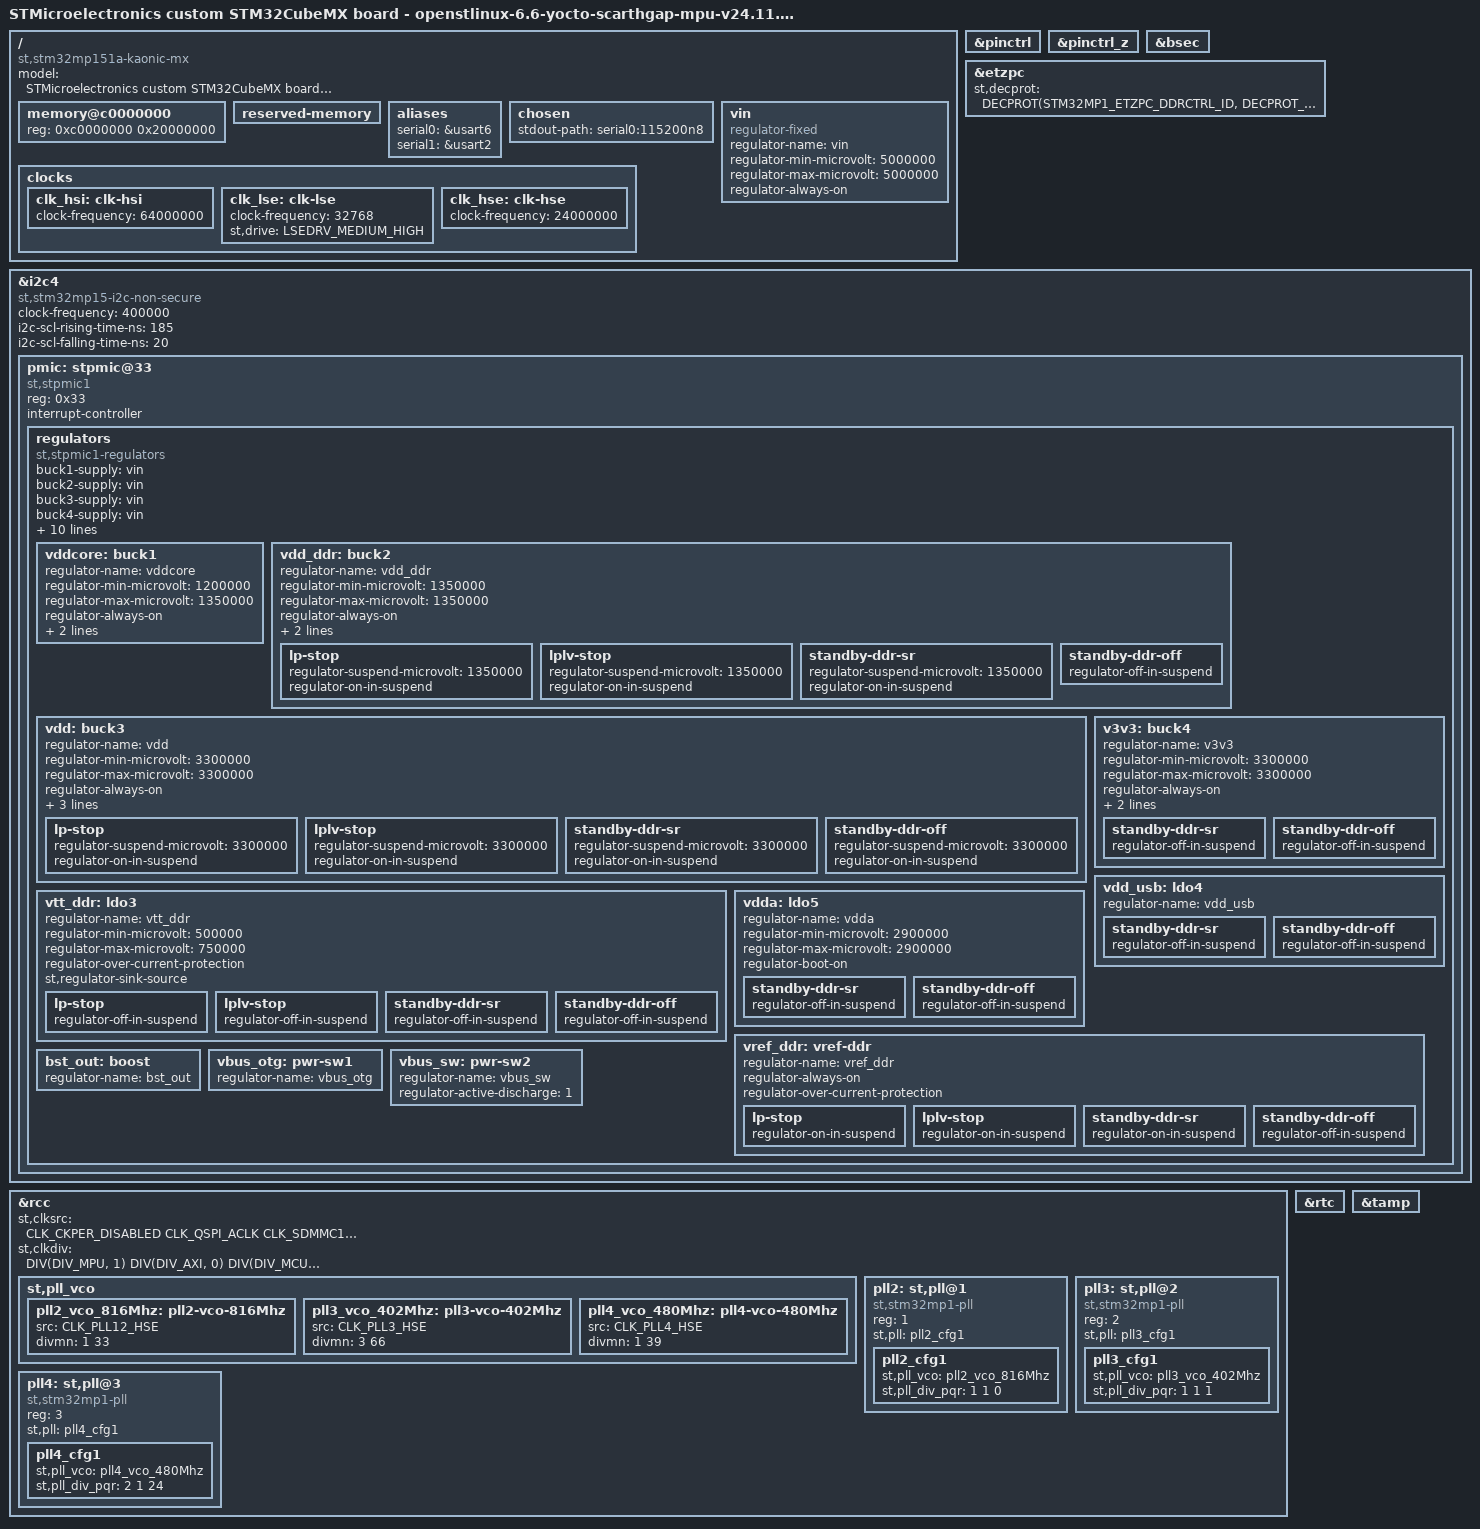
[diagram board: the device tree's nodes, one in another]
// SPDX-License-Identifier: (GPL-2.0-or-later OR BSD-3-Clause)
/*
 * Copyright (C) 2025, STMicroelectronics - All Rights Reserved
 * Author: STM32CubeMX code generation for STMicroelectronics.
 */

/* For more information on Device Tree configuration, please refer to
 * https://wiki.st.com/stm32mpu/wiki/Category:Device_tree_configuration
 */

/dts-v1/;

#include <dt-bindings/pinctrl/stm32-pinfunc.h>
#include <dt-bindings/clock/stm32mp1-clksrc.h>
#include <dt-bindings/soc/stm32mp15-etzpc.h>
#include "stm32mp151.dtsi"
#include "stm32mp15xa.dtsi"
#include "stm32mp15xxab-pinctrl.dtsi"

/* USER CODE BEGIN includes */
#include <dt-bindings/mfd/st,stpmic1.h>
/* USER CODE END includes */

/ {
	model = "STMicroelectronics custom STM32CubeMX board - openstlinux-6.6-yocto-scarthgap-mpu-v24.11.06";
	compatible = "st,stm32mp151a-kaonic-mx", "st,stm32mp151";

	memory@c0000000 {
		device_type = "memory";
		reg = <0xc0000000 0x20000000>;

		/* USER CODE BEGIN memory */
		/* USER CODE END memory */
	};

	reserved-memory {
		#address-cells = <1>;
		#size-cells = <1>;
		ranges;

		/* USER CODE BEGIN reserved-memory */
		/* USER CODE END reserved-memory */
	};

	/* USER CODE BEGIN root */

	aliases {
		serial0 = &usart6;
		serial1 = &usart2;
	};

	chosen {
		stdout-path = "serial0:115200n8";
	};


	vin: vin {
		compatible = "regulator-fixed";
		regulator-name = "vin";
		regulator-min-microvolt = <5000000>;
		regulator-max-microvolt = <5000000>;
		regulator-always-on;
	};

	/* USER CODE END root */

	clocks {
		/* USER CODE BEGIN clocks */
		/* USER CODE END clocks */

		clk_hsi: clk-hsi {
			clock-frequency = <64000000>;

			/* USER CODE BEGIN clk_hsi */
			/* USER CODE END clk_hsi */
		};
		clk_lse: clk-lse {
			clock-frequency = <32768>;
			st,drive = < LSEDRV_MEDIUM_HIGH >;

			/* USER CODE BEGIN clk_lse */
			/* USER CODE END clk_lse */
		};
		clk_hse: clk-hse {
			clock-frequency = <24000000>;

			/* USER CODE BEGIN clk_hse */
			/* USER CODE END clk_hse */
		};
	};

}; /*root*/

/*Warning: the configuration of the secured GPIOs should be added in (addons) User Section*/
&pinctrl {
	/* USER CODE BEGIN pinctrl */
	/* USER CODE END pinctrl */
};

&pinctrl_z {
	/* USER CODE BEGIN pinctrl_z */
	/* USER CODE END pinctrl_z */
};

&bsec {
	status = "okay";

	/* USER CODE BEGIN bsec */
	/* USER CODE END bsec */
};

&etzpc {
	status = "okay";
	st,decprot = <
	/*"NS_R S_W" peripherals*/
	DECPROT(STM32MP1_ETZPC_DDRCTRL_ID, DECPROT_NS_R_S_W, DECPROT_LOCK)
	DECPROT(STM32MP1_ETZPC_DDRPHYC_ID, DECPROT_NS_R_S_W, DECPROT_LOCK)
	/*"Non Secured" peripherals*/
	DECPROT(STM32MP1_ETZPC_DMA1_ID, DECPROT_NS_RW, DECPROT_UNLOCK)
	DECPROT(STM32MP1_ETZPC_DMAMUX_ID, DECPROT_NS_RW, DECPROT_UNLOCK)
	DECPROT(STM32MP1_ETZPC_I2C2_ID, DECPROT_NS_RW, DECPROT_UNLOCK)
	DECPROT(STM32MP1_ETZPC_I2C4_ID, DECPROT_NS_RW, DECPROT_UNLOCK)
	DECPROT(STM32MP1_ETZPC_QSPI_ID, DECPROT_NS_RW, DECPROT_UNLOCK)
	DECPROT(STM32MP1_ETZPC_DLYBQ_ID, DECPROT_NS_RW, DECPROT_UNLOCK)
	DECPROT(STM32MP1_ETZPC_SPI3_ID, DECPROT_NS_RW, DECPROT_UNLOCK)
	DECPROT(STM32MP1_ETZPC_SPI4_ID, DECPROT_NS_RW, DECPROT_UNLOCK)
	DECPROT(STM32MP1_ETZPC_SPI6_ID, DECPROT_NS_RW, DECPROT_UNLOCK)
	DECPROT(STM32MP1_ETZPC_USART2_ID, DECPROT_NS_RW, DECPROT_UNLOCK)
	DECPROT(STM32MP1_ETZPC_USART6_ID, DECPROT_NS_RW, DECPROT_UNLOCK)
	DECPROT(STM32MP1_ETZPC_OTG_ID, DECPROT_NS_RW, DECPROT_UNLOCK)
	/*"Secured" peripherals*/
	DECPROT(STM32MP1_ETZPC_STGENC_ID, DECPROT_S_RW, DECPROT_UNLOCK)
	/*"Mcu Isolation" peripherals*/
	DECPROT(STM32MP1_ETZPC_DMA2_ID, DECPROT_MCU_ISOLATION, DECPROT_UNLOCK)

	/*Restriction: following IDs are not managed  - please to use User-Section if needed:
		  STM32MP1_ETZPC_SRAMx_ID  STM32MP1_ETZPC_RETRAM_ID  STM32MP1_ETZPC_BKPSRAM_ID*/

	/* USER CODE BEGIN etzpc_decprot */
		/*STM32CubeMX generates a basic and standard configuration for ETZPC.
		Additional device configurations can be added here if needed.
		"etzpc" node could be also overloaded in "addons" User-Section.*/
	/* USER CODE END etzpc_decprot */
	>;

	/* USER CODE BEGIN etzpc */
	/* USER CODE END etzpc */
};

&i2c4 {
	status = "okay";

	/* USER CODE BEGIN i2c4 */
	compatible = "st,stm32mp15-i2c-non-secure";

	clock-frequency = <400000>;
	i2c-scl-rising-time-ns = <185>;
	i2c-scl-falling-time-ns = <20>;

	pmic: stpmic@33 {
		compatible = "st,stpmic1";
		reg = <0x33>;
		interrupt-controller;
		#interrupt-cells = <2>;
		status = "okay";

		regulators {
			compatible = "st,stpmic1-regulators";

			buck1-supply = <&vin>;
			buck2-supply = <&vin>;
			buck3-supply = <&vin>;
			buck4-supply = <&vin>;

			ldo1-supply = <&v3v3>;
			ldo2-supply = <&vin>;
			ldo3-supply = <&vdd_ddr>;
			ldo4-supply = <&vin>;
			ldo5-supply = <&vin>;
			ldo6-supply = <&v3v3>;

			vref_ddr-supply = <&vin>;
			boost-supply = <&vin>;

			pwr_sw1-supply = <&bst_out>;
			pwr_sw2-supply = <&bst_out>;

			vddcore: buck1 {
				regulator-name = "vddcore";
				regulator-min-microvolt = <1200000>;
				regulator-max-microvolt = <1350000>;
				regulator-always-on;
				regulator-initial-mode = <0>;
				regulator-over-current-protection;
			};

			vdd_ddr: buck2 {
				regulator-name = "vdd_ddr";
				regulator-min-microvolt = <1350000>;
				regulator-max-microvolt = <1350000>;
				regulator-always-on;
				regulator-initial-mode = <0>;
				regulator-over-current-protection;

				lp-stop {
					regulator-suspend-microvolt = <1350000>;
					regulator-on-in-suspend;
				};

				lplv-stop {
					regulator-suspend-microvolt = <1350000>;
					regulator-on-in-suspend;
				};

				standby-ddr-sr {
					regulator-suspend-microvolt = <1350000>;
					regulator-on-in-suspend;
				};

				standby-ddr-off {
					regulator-off-in-suspend;
				};
			};

			vdd: buck3 {
				regulator-name = "vdd";
				regulator-min-microvolt = <3300000>;
				regulator-max-microvolt = <3300000>;
				regulator-always-on;
				st,mask-reset;
				regulator-initial-mode = <0>;
				regulator-over-current-protection;

				lp-stop {
					regulator-suspend-microvolt = <3300000>;
					regulator-on-in-suspend;
				};

				lplv-stop {
					regulator-suspend-microvolt = <3300000>;
					regulator-on-in-suspend;
				};

				standby-ddr-sr {
					regulator-suspend-microvolt = <3300000>;
					regulator-on-in-suspend;
				};

				standby-ddr-off {
					regulator-suspend-microvolt = <3300000>;
					regulator-on-in-suspend;
				};
			};

			v3v3: buck4 {
				regulator-name = "v3v3";
				regulator-min-microvolt = <3300000>;
				regulator-max-microvolt = <3300000>;
				regulator-always-on;
				regulator-over-current-protection;
				regulator-initial-mode = <0>;

				standby-ddr-sr {
					regulator-off-in-suspend;
				};

				standby-ddr-off {
					regulator-off-in-suspend;
				};
			};

			vtt_ddr: ldo3 {
				regulator-name = "vtt_ddr";
				regulator-min-microvolt = <500000>;
				regulator-max-microvolt = <750000>;
				regulator-over-current-protection;
				st,regulator-sink-source;

				lp-stop {
					regulator-off-in-suspend;
				};

				lplv-stop {
					regulator-off-in-suspend;
				};

				standby-ddr-sr {
					regulator-off-in-suspend;
				};

				standby-ddr-off {
					regulator-off-in-suspend;
				};
			};

			vdd_usb: ldo4 {
				regulator-name = "vdd_usb";

				standby-ddr-sr {
					regulator-off-in-suspend;
				};

				standby-ddr-off {
					regulator-off-in-suspend;
				};
			};

			vdda: ldo5 {
				regulator-name = "vdda";
				regulator-min-microvolt = <2900000>;
				regulator-max-microvolt = <2900000>;
				regulator-boot-on;

				standby-ddr-sr {
					regulator-off-in-suspend;
				};

				standby-ddr-off {
					regulator-off-in-suspend;
				};
			};

			vref_ddr: vref-ddr {
				regulator-name = "vref_ddr";
				regulator-always-on;
				regulator-over-current-protection;

				lp-stop {
					regulator-on-in-suspend;
				};

				lplv-stop {
					regulator-on-in-suspend;
				};

				standby-ddr-sr {
					regulator-on-in-suspend;
				};

				standby-ddr-off {
					regulator-off-in-suspend;
				};
			};

			bst_out: boost {
				regulator-name = "bst_out";
			};

			vbus_otg: pwr-sw1 {
				regulator-name = "vbus_otg";
			};

			vbus_sw: pwr-sw2 {
				regulator-name = "vbus_sw";
				regulator-active-discharge = <1>;
			};
		};
	};

	/* USER CODE END i2c4 */
};

&rcc {
	status = "okay";

	/* USER CODE BEGIN rcc */
	/* USER CODE END rcc */

	st,clksrc = <
		CLK_CKPER_DISABLED
		CLK_QSPI_ACLK
		CLK_SDMMC12_HCLK6
		CLK_STGEN_HSI
		CLK_SPI2S23_PLL4P
		CLK_SPI45_PCLK2
		CLK_SPI6_PCLK5
		CLK_I2C46_PCLK5
		CLK_USBO_PLL4R
		CLK_I2C12_PCLK1
		CLK_UART24_PCLK1
		CLK_UART6_PCLK2
		CLK_MPU_HSI
		CLK_AXI_HSE
		CLK_MCU_PLL3P
		CLK_RTC_LSE
		CLK_MCO1_DISABLED
		CLK_MCO2_DISABLED
	>;
	st,clkdiv = <
		DIV(DIV_MPU, 1)
		DIV(DIV_AXI, 0)
		DIV(DIV_MCU, 0)
		DIV(DIV_APB1, 1)
		DIV(DIV_APB2, 1)
		DIV(DIV_APB3, 1)
		DIV(DIV_APB4, 0)
		DIV(DIV_APB5, 0)
		DIV(DIV_RTC, 0)
		DIV(DIV_MCO1, 0)
		DIV(DIV_MCO2, 0)
	>;
	st,pll_vco {
		pll2_vco_816Mhz: pll2-vco-816Mhz {
			src = < CLK_PLL12_HSE >;
			divmn = < 1 33 >;
		};
		pll3_vco_402Mhz: pll3-vco-402Mhz {
			src = < CLK_PLL3_HSE >;
			divmn = < 3 66 >;
		};
		pll4_vco_480Mhz: pll4-vco-480Mhz {
			src = < CLK_PLL4_HSE >;
			divmn = < 1 39 >;
		};
		/* USER CODE BEGIN rcc_st-pll_vco */
		/* USER CODE END rcc_st-pll_vco */
	};

	pll2:st,pll@1 {
		compatible = "st,stm32mp1-pll";
		reg = <1>;

		st,pll = < &pll2_cfg1 >;

		pll2_cfg1: pll2_cfg1 {
			st,pll_vco = < &pll2_vco_816Mhz >;
			st,pll_div_pqr = < 1 1 0 >;
		};
		/* USER CODE BEGIN pll2 */
		/* USER CODE END pll2 */
	};

	pll3:st,pll@2 {
		compatible = "st,stm32mp1-pll";
		reg = <2>;

		st,pll = < &pll3_cfg1 >;

		pll3_cfg1: pll3_cfg1 {
			st,pll_vco = < &pll3_vco_402Mhz >;
			st,pll_div_pqr = < 1 1 1 >;
		};
		/* USER CODE BEGIN pll3 */
		/* USER CODE END pll3 */
	};

	pll4:st,pll@3 {
		compatible = "st,stm32mp1-pll";
		reg = <3>;

		st,pll = < &pll4_cfg1 >;

		pll4_cfg1: pll4_cfg1 {
			st,pll_vco = < &pll4_vco_480Mhz >;
			st,pll_div_pqr = < 2 1 24 >;
		};
		/* USER CODE BEGIN pll4 */
		/* USER CODE END pll4 */
	};

};

&rtc {
	status = "okay";

	/* USER CODE BEGIN rtc */
	/* USER CODE END rtc */
};

&tamp {
	status = "okay";

	/* USER CODE BEGIN tamp */
	/* USER CODE END tamp */
};

/* USER CODE BEGIN addons */

/* USER CODE END addons */

